# STM32L451 register map
File version: 1.0
CPU: CM4 r0p1, little endian, MPU, FPU, 4 interrupt priority bits
Registers are 32-bit, read-write, reset 0x0 unless marked. A register's access mark holds for its fields unless they carry their own. Offsets are from the block's base; [hi:lo] are bit positions.

## CRS — Clock recovery system
Base 0x40006000
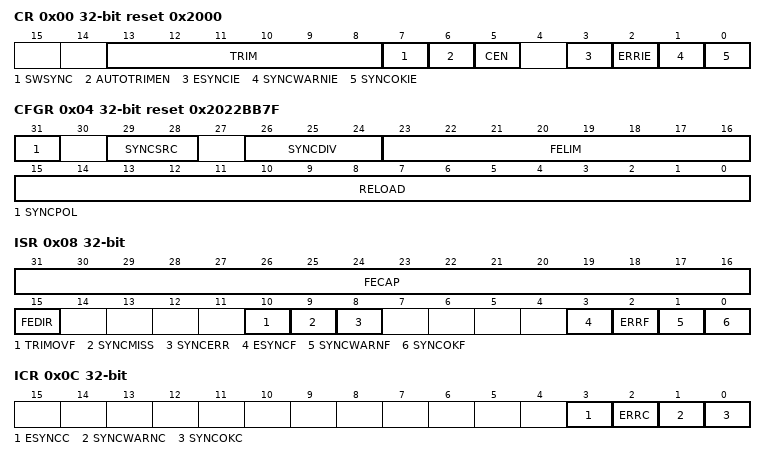
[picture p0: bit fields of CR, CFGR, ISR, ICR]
0x00 CR reset 0x2000 — control register
  [13:8] TRIM — HSI48 oscillator smooth trimming
  [7] SWSYNC — Generate software SYNC event
  [6] AUTOTRIMEN — Automatic trimming enable
  [5] CEN — Frequency error counter enable
  [3] ESYNCIE — Expected SYNC interrupt enable
  [2] ERRIE — Synchronization or trimming error interrupt enable
  [1] SYNCWARNIE — SYNC warning interrupt enable
  [0] SYNCOKIE — SYNC event OK interrupt enable
0x04 CFGR reset 0x2022BB7F — configuration register
  [31] SYNCPOL — SYNC polarity selection
  [29:28] SYNCSRC — SYNC signal source selection
  [26:24] SYNCDIV — SYNC divider
  [23:16] FELIM — Frequency error limit
  [15:0] RELOAD — Counter reload value
0x08 ISR ro — interrupt and status register
  [31:16] FECAP — Frequency error capture
  [15] FEDIR — Frequency error direction
  [10] TRIMOVF — Trimming overflow or underflow
  [9] SYNCMISS — SYNC missed
  [8] SYNCERR — SYNC error
  [3] ESYNCF — Expected SYNC flag
  [2] ERRF — Error flag
  [1] SYNCWARNF — SYNC warning flag
  [0] SYNCOKF — SYNC event OK flag
0x0C ICR — interrupt flag clear register
  [3] ESYNCC — Expected SYNC clear flag
  [2] ERRC — Error clear flag
  [1] SYNCWARNC — SYNC warning clear flag
  [0] SYNCOKC — SYNC event OK clear flag

## QUADSPI — QuadSPI interface
Base 0xA0001000
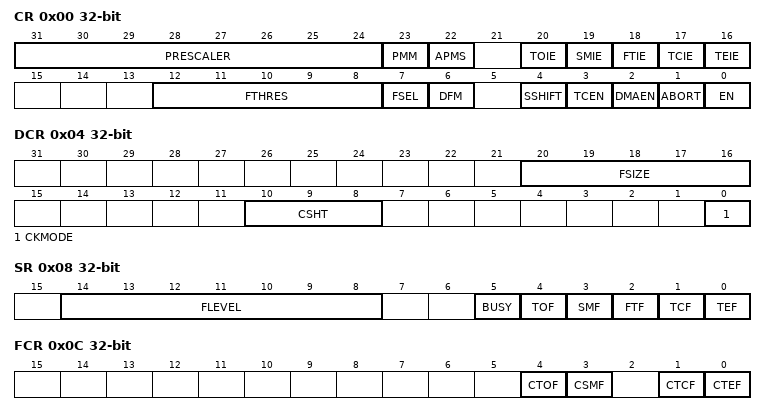
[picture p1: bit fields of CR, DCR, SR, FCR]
0x00 CR — control register
  [31:24] PRESCALER — Clock prescaler
  [23] PMM — Polling match mode
  [22] APMS — Automatic poll mode stop
  [20] TOIE — TimeOut interrupt enable
  [19] SMIE — Status match interrupt enable
  [18] FTIE — FIFO threshold interrupt enable
  [17] TCIE — Transfer complete interrupt enable
  [16] TEIE — Transfer error interrupt enable
  [12:8] FTHRES — IFO threshold level
  [7] FSEL — FLASH memory selection
  [6] DFM — Dual-flash mode
  [4] SSHIFT — Sample shift
  [3] TCEN — Timeout counter enable
  [2] DMAEN — DMA enable
  [1] ABORT — Abort request
  [0] EN — Enable
0x04 DCR — device configuration register
  [20:16] FSIZE — FLASH memory size
  [10:8] CSHT — Chip select high time
  [0] CKMODE — Mode 0 / mode 3
0x08 SR ro — status register
  [14:8] FLEVEL — FIFO level
  [5] BUSY
  [4] TOF — Timeout flag
  [3] SMF — Status match flag
  [2] FTF — FIFO threshold flag
  [1] TCF — Transfer complete flag
  [0] TEF — Transfer error flag
0x0C FCR — flag clear register
  [4] CTOF — Clear timeout flag
  [3] CSMF — Clear status match flag
  [1] CTCF — Clear transfer complete flag
  [0] CTEF — Clear transfer error flag
0x10 DLR — data length register
  [31:0] DL — Data length
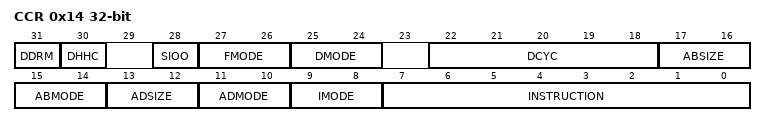
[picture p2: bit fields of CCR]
0x14 CCR — communication configuration register
  [31] DDRM — Double data rate mode
  [30] DHHC — DDR hold half cycle
  [28] SIOO — Send instruction only once mode
  [27:26] FMODE — Functional mode
  [25:24] DMODE — Data mode
  [22:18] DCYC — Number of dummy cycles
  [17:16] ABSIZE — Alternate bytes size
  [15:14] ABMODE — Alternate bytes mode
  [13:12] ADSIZE — Address size
  [11:10] ADMODE — Address mode
  [9:8] IMODE — Instruction mode
  [7:0] INSTRUCTION
0x18 AR — address register
  [31:0] ADDRESS
0x1C ABR
  [31:0] ALTERNATE
0x20 DR — data register
  [31:0] DATA
0x24 PSMKR — polling status mask register
  [31:0] MASK — Status mask
0x28 PSMAR — polling status match register
  [31:0] MATCH — Status match
0x2C PIR — polling interval register
  [15:0] INTERVAL — Polling interval
0x30 LPTR — low-power timeout register
  [15:0] TIMEOUT — Timeout period

## DBGMCU — MCU debug component
Base 0xE0042000
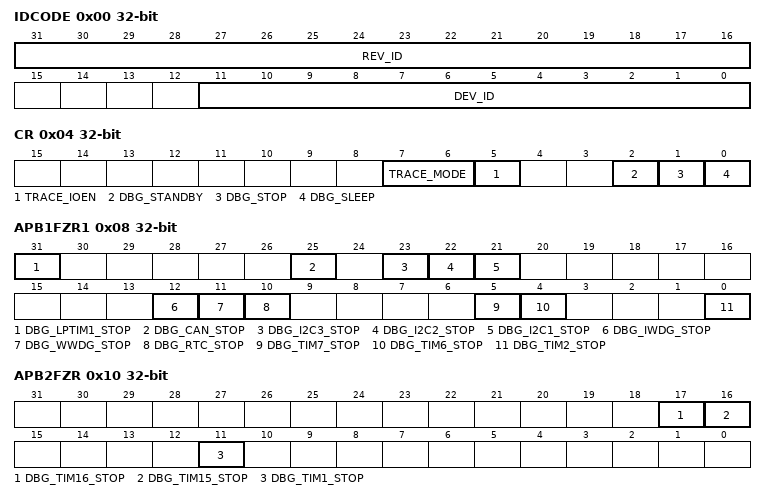
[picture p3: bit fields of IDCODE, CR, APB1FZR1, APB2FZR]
0x00 IDCODE ro — DBGMCU_IDCODE
  [31:16] REV_ID — Revision identifie
  [11:0] DEV_ID — Device identifier
0x04 CR — Debug MCU configuration register
  [7:6] TRACE_MODE — Trace pin assignment control
  [5] TRACE_IOEN — Trace pin assignment control
  [2] DBG_STANDBY — Debug Standby mode
  [1] DBG_STOP — Debug Stop mode
  [0] DBG_SLEEP — Debug Sleep mode
0x08 APB1FZR1 — Debug MCU APB1 freeze register1
  [31] DBG_LPTIM1_STOP — LPTIM1 counter stopped when core is halted
  [25] DBG_CAN_STOP — bxCAN stopped when core is halted
  [23] DBG_I2C3_STOP — I2C3 SMBUS timeout counter stopped when core is halted
  [22] DBG_I2C2_STOP — I2C2 SMBUS timeout counter stopped when core is halted
  [21] DBG_I2C1_STOP — I2C1 SMBUS timeout counter stopped when core is halted
  [12] DBG_IWDG_STOP — Independent watchdog counter stopped when core is halted
  [11] DBG_WWDG_STOP — Window watchdog counter stopped when core is halted
  [10] DBG_RTC_STOP — RTC counter stopped when core is halted
  [5] DBG_TIM7_STOP — TIM7 counter stopped when core is halted
  [4] DBG_TIM6_STOP — TIM6 counter stopped when core is halted
  [0] DBG_TIM2_STOP — TIM2 counter stopped when core is halted
0x0C APB1FZR2 — Debug MCU APB1 freeze register 2
  [5] DBG_LPTIM2_STOP — LPTIM2 counter stopped when core is halted
0x10 APB2FZR — Debug MCU APB2 freeze register
  [17] DBG_TIM16_STOP — TIM16 counter stopped when core is halted
  [16] DBG_TIM15_STOP — TIM15 counter stopped when core is halted
  [11] DBG_TIM1_STOP — TIM1 counter stopped when core is halted

## Notices in the file
Copyright (c) 2024 STMicroelectronics.
SPDX-License-Identifier: Apache-2.0
Licensed under the Apache License, Version 2.0 (the "License");
you may not use this file except in compliance with the License.
You may obtain a copy of the License at
http://www.apache.org/licenses/LICENSE-2.0
Unless required by applicable law or agreed to in writing, software
distributed under the License is distributed on an "AS IS" BASIS,
WITHOUT WARRANTIES OR CONDITIONS OF ANY KIND, either express or implied.
See the License for the specific language governing permissions and
limitations under the License.
